# MK22F10 register map
File version: 1.6
Registers are 32-bit, read-write, reset 0x0 unless marked. A register's access mark holds for its fields unless they carry their own. Offsets are from the block's base; [hi:lo] are bit positions; {n}, {i} and the like mark numbered series; 'fields as' and 'values as' point back to an identical list.

## SysTick — System timer
Base 0xE000E010; register names take the prefix SYST_
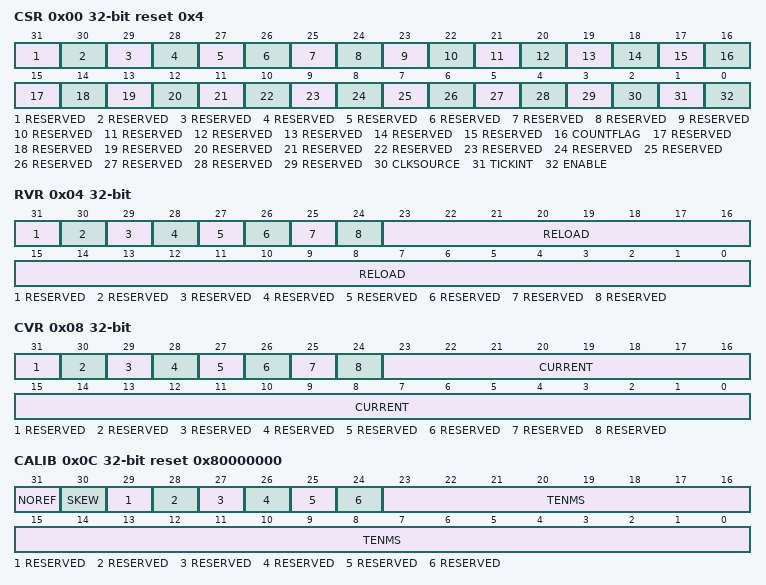
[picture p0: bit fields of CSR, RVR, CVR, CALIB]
0x00 CSR reset 0x4 — SysTick Control and Status Register
  [31] RESERVED ro
  [30] RESERVED ro
  [29] RESERVED ro
  [28] RESERVED ro
  [27] RESERVED ro
  [26] RESERVED ro
  [25] RESERVED ro
  [24] RESERVED ro
  [23] RESERVED ro
  [22] RESERVED ro
  [21] RESERVED ro
  [20] RESERVED ro
  [19] RESERVED ro
  [18] RESERVED ro
  [17] RESERVED ro
  [16] COUNTFLAG
  [15] RESERVED ro
  [14] RESERVED ro
  [13] RESERVED ro
  [12] RESERVED ro
  [11] RESERVED ro
  [10] RESERVED ro
  [9] RESERVED ro
  [8] RESERVED ro
  [7] RESERVED ro
  [6] RESERVED ro
  [5] RESERVED ro
  [4] RESERVED ro
  [3] RESERVED ro
  [2] CLKSOURCE
    0=external clock; 1=processor clock
  [1] TICKINT
    0=counting down to 0 does not assert the SysTick exception request; 1=counting down to 0 asserts the SysTick exception request
  [0] ENABLE
    0=counter disabled; 1=counter enabled
0x04 RVR — SysTick Reload Value Register
  [31] RESERVED ro
  [30] RESERVED ro
  [29] RESERVED ro
  [28] RESERVED ro
  [27] RESERVED ro
  [26] RESERVED ro
  [25] RESERVED ro
  [24] RESERVED ro
  [23:0] RELOAD — Value to load into the SysTick Current Value Register when the counter reaches 0
0x08 CVR — SysTick Current Value Register
  [31] RESERVED ro
  [30] RESERVED ro
  [29] RESERVED ro
  [28] RESERVED ro
  [27] RESERVED ro
  [26] RESERVED ro
  [25] RESERVED ro
  [24] RESERVED ro
  [23:0] CURRENT — Current value at the time the register is accessed
0x0C CALIB ro reset 0x80000000 — SysTick Calibration Value Register
  [31] NOREF
    0=The reference clock is provided; 1=The reference clock is not provided
  [30] SKEW
    0=10ms calibration value is exact; 1=10ms calibration value is inexact, because of the clock frequency
  [29] RESERVED
  [28] RESERVED
  [27] RESERVED
  [26] RESERVED
  [25] RESERVED
  [24] RESERVED
  [23:0] TENMS — Reload value to use for 10ms timing

## NVIC — Nested Vectored Interrupt Controller
Base 0xE000E100
{0x0+4i} NVICISER{i} (i=0..3) — Interrupt Set Enable Register n
  [31:0] SETENA — Interrupt set enable bits
{0x80+4i} NVICICER{i} (i=0..3) — Interrupt Clear Enable Register n
  [31:0] CLRENA — Interrupt clear-enable bits
{0x100+4i} NVICISPR{i} (i=0..3) — Interrupt Set Pending Register n
  [31:0] SETPEND — Interrupt set-pending bits
{0x180+4i} NVICICPR{i} (i=0..3) — Interrupt Clear Pending Register n
  [31:0] CLRPEND — Interrupt clear-pending bits
{0x200+4i} NVICIABR{i} (i=0..3) — Interrupt Active bit Register n
  [31:0] ACTIVE — Interrupt active flags
{0x300+i} NVICIP{i} 8-bit (i=0..105) — Interrupt Priority Register n
  [7:0] PRI{i} — Priority of interrupt {i}
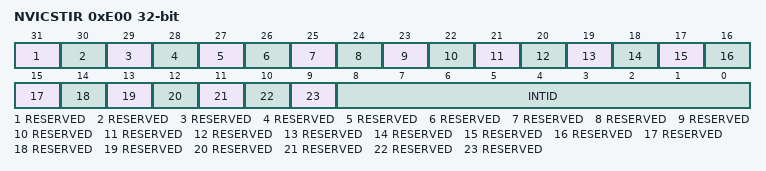
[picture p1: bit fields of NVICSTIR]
0xE00 NVICSTIR — Software Trigger Interrupt Register
  [31] RESERVED
  [30] RESERVED
  [29] RESERVED
  [28] RESERVED
  [27] RESERVED
  [26] RESERVED
  [25] RESERVED
  [24] RESERVED
  [23] RESERVED
  [22] RESERVED
  [21] RESERVED
  [20] RESERVED
  [19] RESERVED
  [18] RESERVED
  [17] RESERVED
  [16] RESERVED
  [15] RESERVED
  [14] RESERVED
  [13] RESERVED
  [12] RESERVED
  [11] RESERVED
  [10] RESERVED
  [9] RESERVED
  [8:0] INTID — Interrupt ID of the interrupt to trigger, in the range 0-239. For example, a value of 0x03 specifies interrupt IRQ3.

## MCM — Core Platform Miscellaneous Control Module
Base 0xE0080000; register names take the prefix MCM_
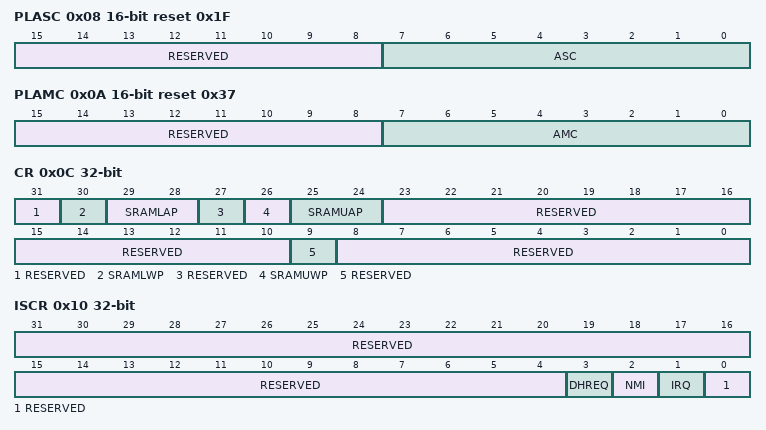
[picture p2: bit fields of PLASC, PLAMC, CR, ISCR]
0x08 PLASC 16-bit ro reset 0x1F — Crossbar Switch (AXBS) Slave Configuration
  [15:8] RESERVED
  [7:0] ASC — Each bit in the ASC field indicates whether there is a corresponding connection to the crossbar switch's slave input port.
    0=A bus slave connection to AXBS input port n is absent; 1=A bus slave connection to AXBS input port n is present
0x0A PLAMC 16-bit ro reset 0x37 — Crossbar Switch (AXBS) Master Configuration
  [15:8] RESERVED
  [7:0] AMC — Each bit in the AMC field indicates whether there is a corresponding connection to the AXBS master input port.
    0=A bus master connection to AXBS input port n is absent; 1=A bus master connection to AXBS input port n is present
0x0C CR — Control Register
  [31] RESERVED ro
  [30] SRAMLWP — SRAM_L Write Protect
  [29:28] SRAMLAP — SRAM_L arbitration priority
    0=Round robin; 1=Special round robin (favors SRAM backoor accesses over the processor); 2=Fixed priority. Processor has highest, backdoor has lowest; 3=Fixed priority. Backdoor has highest, processor has lowest
  [27] RESERVED ro
  [26] SRAMUWP — SRAM_U write protect
  [25:24] SRAMUAP — SRAM_U arbitration priority
    values as SRAMLAP
  [23:10] RESERVED ro
  [9] RESERVED ro
  [8:0] RESERVED ro
0x10 ISCR — Interrupt Status Register
  [31:4] RESERVED ro
  [3] DHREQ ro — Debug Halt Request Indicator
    0=No debug halt request; 1=Debug halt request initiated
  [2] NMI — Non-maskable Interrupt Pending
    0=No pending NMI; 1=Due to the ETB counter expiring, an NMI is pending
  [1] IRQ — Normal Interrupt Pending
    0=No pending interrupt; 1=Due to the ETB counter expiring, a normal interrupt is pending
  [0] RESERVED ro
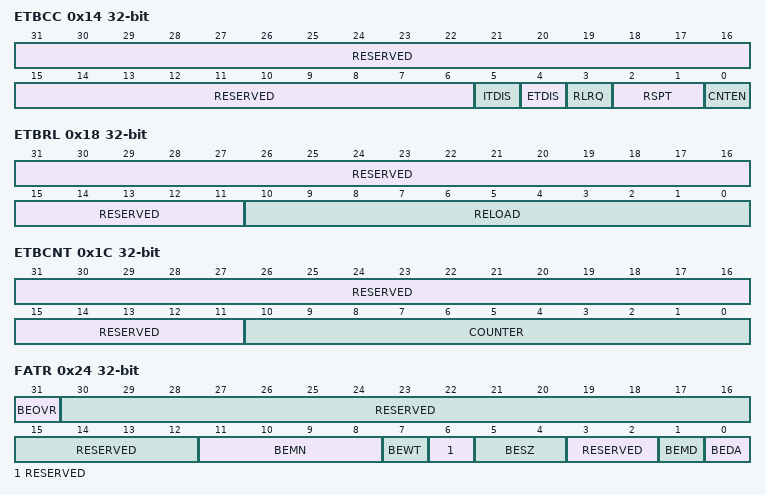
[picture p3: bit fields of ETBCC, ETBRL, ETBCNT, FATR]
0x14 ETBCC — ETB Counter Control register
  [31:6] RESERVED ro
  [5] ITDIS — ITM-To-TPIU Disable
    0=ITM-to-TPIU trace path enabled; 1=ITM-to-TPIU trace path disabled
  [4] ETDIS — ETM-To-TPIU Disable
    0=ETM-to-TPIU trace path enabled; 1=ETM-to-TPIU trace path disabled
  [3] RLRQ — Reload Request
    0=No effect; 1=Clears pending debug halt, NMI, or IRQ interrupt requests
  [2:1] RSPT — Response Type
    0=No response when the ETB count expires; 1=Generate a normal interrupt when the ETB count expires; 2=Generate an NMI when the ETB count expires; 3=Generate a debug halt when the ETB count expires
  [0] CNTEN — Counter Enable
    0=ETB counter disabled; 1=ETB counter enabled
0x18 ETBRL — ETB Reload register
  [31:11] RESERVED ro
  [10:0] RELOAD — Byte Count Reload Value
0x1C ETBCNT ro — ETB Counter Value register
  [31:11] RESERVED
  [10:0] COUNTER — Byte Count Counter Value
0x20 FADR ro reset not defined — Fault address register
  [31:0] ADDRESS — Fault address
0x24 FATR ro reset not defined — Fault attributes register
  [31] BEOVR — Bus error overrun
    0=No bus error overrun; 1=Bus error overrun occurred. The FADR and FDR registers and the other FATR bits are not updated to reflect this new bus error.
  [30:12] RESERVED
  [11:8] BEMN — Bus error master number
  [7] BEWT — Bus error write
    0=Read access; 1=Write access
  [6] RESERVED
  [5:4] BESZ — Bus error size
    0=8-bit access; 1=16-bit access; 2=32-bit access
  [3:2] RESERVED
  [1] BEMD — Bus error privilege level
    0=User mode; 1=Supervisor/privileged mode
  [0] BEDA — Bus error access type
    0=Instruction; 1=Data
0x28 FDR ro reset not defined — Fault data register
  [31:0] DATA — Fault data
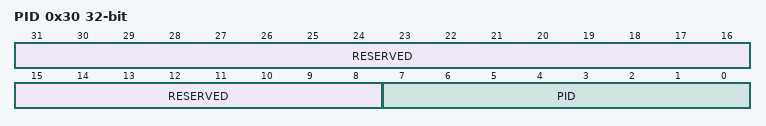
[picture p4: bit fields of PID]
0x30 PID — Process ID register
  [31:8] RESERVED ro
  [7:0] PID — M0_PID And M1_PID For MPU
